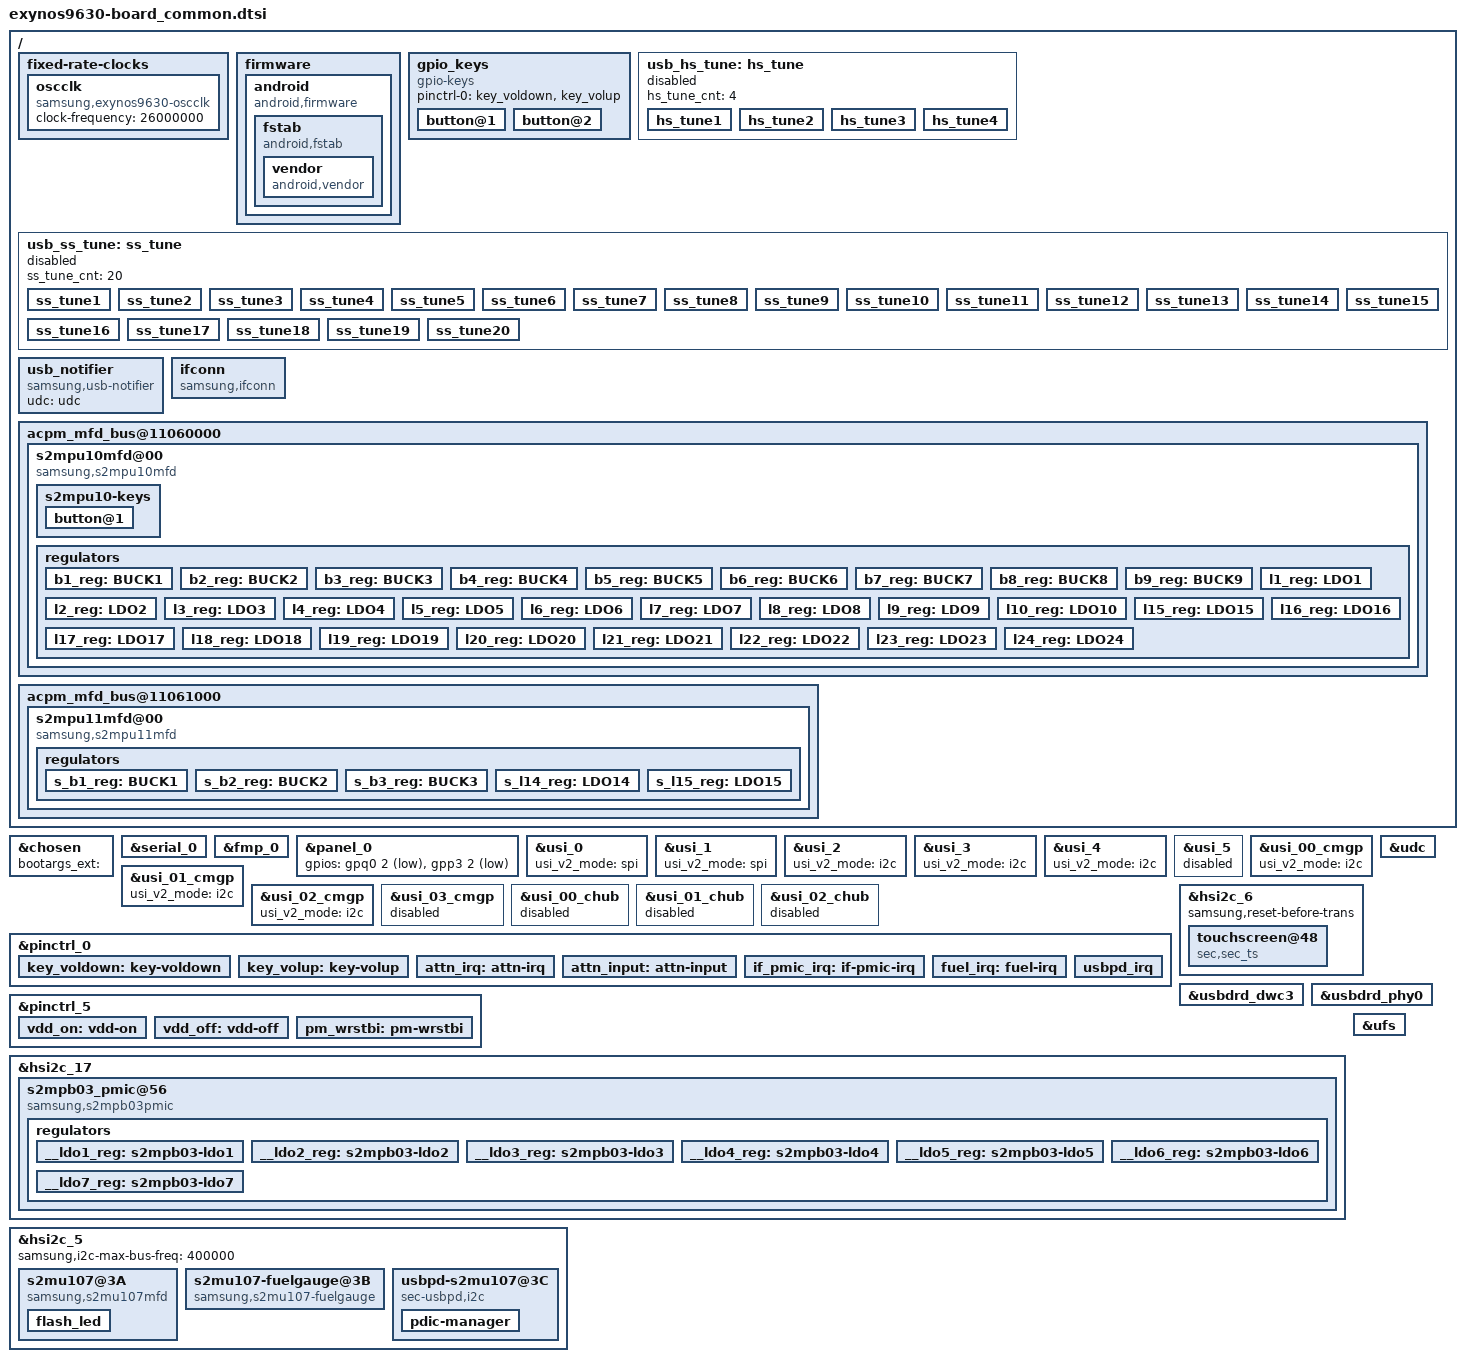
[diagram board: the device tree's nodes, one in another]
/*
 * SAMSUNG EXYNOS9630 board common device tree source
 *
 * Copyright (c) 2019 Samsung Electronics Co., Ltd.
 *		http://www.samsung.com
 *
 * This program is free software; you can redistribute it and/or modify
 * it under the terms of the GNU General Public License version 2 as
 * published by the Free Software Foundation.
 */

#include <dt-bindings/interrupt-controller/exynos9630.h>

/ {
	fragment@common {
		target-path = "/";
		__overlay__ {
			#address-cells = <2>;
			#size-cells = <1>;

			fixed-rate-clocks {
				oscclk {
					compatible = "samsung,exynos9630-oscclk";
					clock-frequency = <26000000>;
				};
			};

			firmware {
				android {
					compatible = "android,firmware";
/*
					vbmeta {
						compatible = "android,vbmeta";
						parts = "vbmeta,boot,system,vendor,dtbo";
					};
*/
					fstab {
						compatible = "android,fstab";
						vendor {
							compatible = "android,vendor";
							dev = "/dev/block/platform/13600000.ufs/by-name/vendor";
							type = "ext4";
							mnt_flags = "ro";
							fsmgr_flags = "wait";
/*
							fsmgr_flags = "wait,avb";
*/
						};
					};
				};
			};

			gpio_keys {
				status = "okay";
				compatible = "gpio-keys";
				pinctrl-names = "default";
				pinctrl-0 = <&key_voldown &key_volup>;

				button@1 {
					label = "gpio-keys: KEY_VOLUMEDOWN";
					linux,code = <114>;
					gpios = <&gpa0 7 0xf>;
				};
				button@2 {
					label = "gpio-keys: KEY_VOLUMEUP";
					linux,code = <115>;
					gpios = <&gpa1 0 0xf>;
				};
			};
			usb_hs_tune:hs_tune {
				status = "disabled";
				hs_tune_cnt = <4>;
				/* value = <device host> */
				hs_tune1 {
					tune_name = "tx_pre_emp";
					tune_value = <0x3 0x3>;
				};

				hs_tune2 {
					tune_name = "tx_vref";
					tune_value = <0xc 0xc>;
				};

				hs_tune3 {
					tune_name = "rx_sqrx";
					tune_value = <0x5 0x5>;
				};

				hs_tune4 {
					tune_name = "utmi_clk";
					tune_value = <0x1 0x1>;
				};
			};

			usb_ss_tune:ss_tune {
				status = "disabled";
				ss_tune_cnt = <20>;
				/* value = <device host> */
				ss_tune1 {
					tune_name = "ssrx_sqhs_th";
					tune_value = <0x4 0x4>;
				};

				ss_tune2 {
					tune_name = "ssrx_lfps_th";
					tune_value = <0x2 0x2>;
				};

				ss_tune3 {
					tune_name = "ssrx_mf_eq_en";
					tune_value = <0x1 0x1>;
				};

				ss_tune4 {
					tune_name = "ssrx_mf_eq_ctrl_ss";
					tune_value = <0x6 0x6>;
				};

				ss_tune5 {
					tune_name = "ssrx_hf_eq_ctrl_ss";
					tune_value = <0xe 0xe>;
				};

				ss_tune6 {
					tune_name = "ssrx_mf_eq_ctrl_ssp";
					tune_value = <0x6 0x6>;
				};

				ss_tune7 {
					tune_name = "ssrx_hf_eq_ctrl_ssp";
					tune_value = <0xe 0xe>;
				};

				ss_tune8 {
					tune_name = "ssrx_dfe1_tap_ctrl";
					tune_value = <0x2 0x2>;
				};

				ss_tune9 {
					tune_name = "ssrx_dfe2_tap_ctrl";
					tune_value = <0x0 0x0>;
				};

				ss_tune10 {
					tune_name = "ssrx_dfe3_tap_ctrl";
					tune_value = <0x0 0x0>;
				};

				ss_tune11 {
					tune_name = "ssrx_dfe4_tap_ctrl";
					tune_value = <0x0 0x0>;
				};

				ss_tune12 {
					tune_name = "ssrx_dfe5_tap_ctrl";
					tune_value = <0x0 0x0>;
				};

				ss_tune13 {
					tune_name = "ssrx_term_cal";
					tune_value = <0xb 0xb>;
				};

				ss_tune14 {
					tune_name = "sstx_amp";
					tune_value = <0xb 0xb>;
				};

				ss_tune15 {
					tune_name = "sstx_deemp";
					tune_value = <0x5 0x5>;
				};

				ss_tune16 {
					tune_name = "sstx_pre_shoot";
					tune_value = <0x3 0x3>;
				};

				ss_tune17 {
					tune_name = "sstx_idrv_up";
					tune_value = <0x7 0x7>;
				};

				ss_tune18 {
					tune_name = "sstx_idrv_dn";
					tune_value = <0x0 0x0>;
				};

				ss_tune19 {
					tune_name = "sstx_up_term";
					tune_value = <0x3 0x3>;
				};

				ss_tune20 {
					tune_name = "sstx_dn_term";
					tune_value = <0x3 0x3>;
				};
			};

			usb_notifier {
				compatible = "samsung,usb-notifier";
				udc = <&udc>;
			};

			ifconn {
				status = "okay";
				compatible = "samsung,ifconn";
				ifconn,usbpd = "s2mu107";
				ifconn,muic = "s2mu107-muic";
			};

			acpm_mfd_bus@11060000 {
				status = "okay";
				#address-cells = <1>;
				#size-cells = <0>;
				s2mpu10mfd@00 {
					compatible = "samsung,s2mpu10mfd";
					acpm-ipc-channel = <2>;
					i2c-speedy-address;
					s2mpu10,wakeup = "enabled";
					reg = <0x00>;
					interrupts = <GIC_SPI INTREQ_COMB_NONSECURE_SYSREG_VGPIO2AP IRQ_TYPE_LEVEL_HIGH>;
					pinctrl-names = "default";
					pinctrl-0 = <&pm_wrstbi &smpl_warn>;
					gpios = <&gpg0 0 0>;
					/* RTC: wtsr/smpl */
					wtsr_en = "enabled"; /* enable */
					smpl_en = "enabled"; /* enable */
					wtsr_timer_val = <3>;	/* 1000ms */
					smpl_timer_val = <4>;	/* 500ms */
					check_jigon = <0>; /* do not check jigon */
					/* RTC: If it's first boot, reset rtc to 1/1/2019 12:00:00(Tue) */
					init_time,sec = <0>;
					init_time,min = <0>;
					init_time,hour = <12>;
					init_time,mday = <1>;
					init_time,mon = <0>;
					init_time,year = <119>;
					init_time,wday = <2>;
					/* SMPL_WARN */
					smpl_warn_en = <1>; /* 1 : enable , 0 : disable */
					/* range of SMPL_WARN_LEVEL */
					/* 0x00 : 2.1V, 0x20 : 2.3V, 0x40 : 2.5V, 0x60 : 2.7V 0x80 : 2.9V */
					/* 0xA0 : 3.1V, 0xC0 : 3.3V */
					smpl_warn_vth = <0x80>;
					/* SMPL_WARN_HYS[4:3] 00(Reserved), 01(200mV), 10(300mV), 11(Reserved) */
					smpl_warn_hys = <0x00>;
					/* OCP_WARN */
					ocp_warn_b2_en = <1>; /* 1 : enable, 0 : disable */
					ocp_warn_b2_cnt = <0>; /* ocp warn reset timing control, 0 : 2 clock, 1 : 32 clock */
					ocp_warn_b2_dvs_mask = <0>; /* ocp warn mask when dvs, 0 : not masked, 1 : masked  */
					ocp_warn_b3_en = <1>; /* 1 : enable, 0 : disable */
					ocp_warn_b3_cnt = <0>; /* ocp warn reset timing control, 0 : 2 clock, 1 : 32 clock */
					ocp_warn_b3_dvs_mask = <0>; /* ocp warn mask when dvs, 0 : not masked, 1 : masked  */

					s2mpu10-keys {
						button@1 {
							label = "pmic-keys: KEY_POWER";
							linux,code = <116>;
							wakeup = <1>;
						};
					};

					regulators {
						b1_reg: BUCK1 {
							regulator-name = "vdd_mif";
							regulator-min-microvolt = <450000>;
							regulator-max-microvolt = <1300000>;
							regulator-always-on;
							regulator-ramp-delay = <12000>;
							regulator-initial-mode = <3>;
						};

						b2_reg: BUCK2 {
							regulator-name = "vdd_cpucl1";
							regulator-min-microvolt = <450000>;
							regulator-max-microvolt = <1300000>;
							regulator-always-on;
							regulator-ramp-delay = <12000>;
							regulator-initial-mode = <3>;
						};

						b3_reg: BUCK3 {
							regulator-name = "vdd_cpucl0";
							regulator-min-microvolt = <450000>;
							regulator-max-microvolt = <1300000>;
							regulator-always-on;
							regulator-ramp-delay = <12000>;
							regulator-initial-mode = <3>;
						};

						b4_reg: BUCK4 {
							regulator-name = "vdd_int";
							regulator-min-microvolt = <450000>;
							regulator-max-microvolt = <1300000>;
							regulator-always-on;
							regulator-ramp-delay = <12000>;
							regulator-initial-mode = <3>;
						};

						b5_reg: BUCK5 {
							regulator-name = "vdd_npu";
							regulator-min-microvolt = <450000>;
							regulator-max-microvolt = <1300000>;
							regulator-always-on;
							regulator-ramp-delay = <12000>;
							regulator-initial-mode = <3>;
						};

						b6_reg: BUCK6 {
							regulator-name = "vdd2_mem";
							regulator-min-microvolt = <900000>;
							regulator-max-microvolt = <1500000>;
							regulator-always-on;
							regulator-ramp-delay = <12000>;
							regulator-initial-mode = <3>;
						};

						b7_reg: BUCK7 {
							regulator-name = "vdd_lldo1";
							regulator-min-microvolt = <900000>;
							regulator-max-microvolt = <1500000>;
							regulator-always-on;
							regulator-ramp-delay = <12000>;
							regulator-initial-mode = <3>;
						};

						b8_reg: BUCK8 {
							regulator-name = "vdd_lldo2";
							regulator-min-microvolt = <900000>;
							regulator-max-microvolt = <1500000>;
							regulator-always-on;
							regulator-ramp-delay = <12000>;
							regulator-initial-mode = <3>;
						};

						b9_reg: BUCK9 {
							regulator-name = "vdd_mldo";
							regulator-min-microvolt = <1750000>;
							regulator-max-microvolt = <2150000>;
							regulator-always-on;
							regulator-ramp-delay = <12000>;
							regulator-initial-mode = <3>;
						};

						l1_reg: LDO1 {
							regulator-name = "vdd_ldo1";
							regulator-min-microvolt = <700000>;
							regulator-max-microvolt = <1300000>;
							regulator-always-on;
							regulator-ramp-delay = <12000>;
							regulator-initial-mode = <3>;
						};

						l2_reg: LDO2 {
							regulator-name = "vdd_ldo2";
							regulator-min-microvolt = <1600000>;
							regulator-max-microvolt = <1950000>;
							regulator-always-on;
							regulator-ramp-delay = <12000>;
							regulator-initial-mode = <3>;
						};

						l3_reg: LDO3 {
							regulator-name = "vdd_ldo3";
							regulator-min-microvolt = <500000>;
							regulator-max-microvolt = <1187500>;
							regulator-always-on;
							regulator-ramp-delay = <12000>;
							regulator-initial-mode = <3>;
						};

						l4_reg: LDO4 {
							regulator-name = "vdd_ldo4";
							regulator-min-microvolt = <700000>;
							regulator-max-microvolt = <1300000>;
							regulator-always-on;
							regulator-ramp-delay = <12000>;
							regulator-initial-mode = <3>;
						};

						l5_reg: LDO5 {
							regulator-name = "vdd_ldo5";
							regulator-min-microvolt = <700000>;
							regulator-max-microvolt = <1300000>;
							regulator-always-on;
							regulator-ramp-delay = <12000>;
							regulator-initial-mode = <3>;
						};

						l6_reg: LDO6 {
							regulator-name = "vdd_ldo6";
							regulator-min-microvolt = <1600000>;
							regulator-max-microvolt = <1950000>;
							regulator-always-on;
							regulator-ramp-delay = <12000>;
							regulator-initial-mode = <3>;
						};

						l7_reg: LDO7 {
							regulator-name = "vdd_ldo7";
							regulator-min-microvolt = <1800000>;
							regulator-max-microvolt = <3375000>;
							regulator-always-on;
							regulator-ramp-delay = <12000>;
							regulator-initial-mode = <3>;
						};

						l8_reg: LDO8 {
							regulator-name = "vdd_ldo8";
							regulator-min-microvolt = <700000>;
							regulator-max-microvolt = <1300000>;
							regulator-always-on;
							regulator-ramp-delay = <12000>;
							regulator-initial-mode = <3>;
						};

						l9_reg: LDO9 {
							regulator-name = "vdd_ldo9";
							regulator-min-microvolt = <1600000>;
							regulator-max-microvolt = <1950000>;
							regulator-always-on;
							regulator-ramp-delay = <12000>;
							regulator-initial-mode = <3>;
						};

						l10_reg: LDO10 {
							regulator-name = "vdd_ldo10";
							regulator-min-microvolt = <1800000>;
							regulator-max-microvolt = <3375000>;
							regulator-always-on;
							regulator-ramp-delay = <12000>;
							regulator-initial-mode = <3>;
						};
/*
						l11_reg: LDO11 {
							regulator-name = "vdd_ldo11";
							regulator-min-microvolt = <450000>;
							regulator-max-microvolt = <1300000>;
							regulator-always-on;
							regulator-ramp-delay = <12000>;
							regulator-initial-mode = <3>;
						};

						l12_reg: LDO12 {
							regulator-name = "vdd_ldo12";
							regulator-min-microvolt = <700000>;
							regulator-max-microvolt = <1300000>;
							regulator-always-on;
							regulator-ramp-delay = <12000>;
							regulator-initial-mode = <3>;
						};

						l13_reg: LDO13 {
							regulator-name = "vdd_ldo13";
							regulator-min-microvolt = <700000>;
							regulator-max-microvolt = <1300000>;
							regulator-always-on;
							regulator-ramp-delay = <12000>;
							regulator-initial-mode = <3>;
						};

						l14_reg: LDO14 {
							regulator-name = "vdd_ldo14";
							regulator-min-microvolt = <1600000>;
							regulator-max-microvolt = <1950000>;
							regulator-always-on;
							regulator-ramp-delay = <12000>;
							regulator-initial-mode = <3>;
						};
*/
						l15_reg: LDO15 {
							regulator-name = "vdd_ldo15";
							regulator-min-microvolt = <1800000>;
							regulator-max-microvolt = <3375000>;
							regulator-always-on;
							regulator-ramp-delay = <12000>;
							regulator-initial-mode = <3>;
						};

						l16_reg: LDO16 {
							regulator-name = "vdd_ldo16";
							regulator-min-microvolt = <1800000>;
							regulator-max-microvolt = <3375000>;
							regulator-always-on;
							regulator-ramp-delay = <12000>;
							regulator-initial-mode = <3>;
						};

						l17_reg: LDO17 {
							regulator-name = "vdd_ldo17";
							regulator-min-microvolt = <1600000>;
							regulator-max-microvolt = <1950000>;
							regulator-ramp-delay = <12000>;
							regulator-initial-mode = <3>;
						};

						l18_reg: LDO18 {
							regulator-name = "vdd_ldo18";
							regulator-min-microvolt = <1800000>;
							regulator-max-microvolt = <3375000>;
							regulator-ramp-delay = <12000>;
							regulator-initial-mode = <3>;
						};

						l19_reg: LDO19 {
							regulator-name = "vdd_ldo19";
							regulator-min-microvolt = <1800000>;
							regulator-max-microvolt = <3375000>;
							regulator-always-on;
							regulator-ramp-delay = <12000>;
							regulator-initial-mode = <3>;
						};

						l20_reg: LDO20 {
							regulator-name = "vdd_ldo20";
							regulator-min-microvolt = <1600000>;
							regulator-max-microvolt = <1950000>;
							regulator-always-on;
							regulator-ramp-delay = <12000>;
							regulator-initial-mode = <3>;
						};

						l21_reg: LDO21 {
							regulator-name = "vdd_ldo21";
							regulator-min-microvolt = <1800000>;
							regulator-max-microvolt = <3375000>;
							regulator-always-on;
							regulator-ramp-delay = <12000>;
							regulator-initial-mode = <3>;
						};

						l22_reg: LDO22 {
							regulator-name = "vdd_ldo22";
							regulator-min-microvolt = <1600000>;
							regulator-max-microvolt = <1950000>;
							regulator-always-on;
							regulator-ramp-delay = <12000>;
							regulator-initial-mode = <3>;
						};

						l23_reg: LDO23 {
							regulator-name = "vdd_ldo23";
							regulator-min-microvolt = <1800000>;
							regulator-max-microvolt = <3375000>;
							regulator-always-on;
							regulator-ramp-delay = <12000>;
							regulator-initial-mode = <3>;
						};

						l24_reg: LDO24 {
							regulator-name = "vdd_ldo24";
							regulator-min-microvolt = <1800000>;
							regulator-max-microvolt = <3375000>;
							regulator-always-on;
							regulator-ramp-delay = <12000>;
							regulator-initial-mode = <3>;
						};
					}; /* end of regulators */
				}; /* end of s2mpu10mfd@00 */
			}; /* end of acpm_mfd_bus@11a10000 */

			acpm_mfd_bus@11061000 {
				status = "okay";
				#address-cells = <1>;
				#size-cells = <0>;
				s2mpu11mfd@00 { /* TODO: node check */
					compatible = "samsung,s2mpu11mfd";
					acpm-ipc-channel = <2>;
					i2c-speedy-address;
					s2mpu11,wakeup = "enabled";
					reg = <0x00>; /* TODO: Check */
					wtsr_en = <1>; /* 0 : disable, 1: enable */
					/* OCP_WARN */
					ocp_warn_b2_en = <1>; /* 1 : enable, 0 : disable */
					ocp_warn_b2_cnt = <0>; /* ocp warn reset timing control, 0 : 2 clock, 1 : 32 clock */
					ocp_warn_b2_dvs_mask = <0>; /* ocp warn mask when dvs, 0 : not masked, 1 : masked  */

					regulators {
						s_b1_reg: BUCK1 {
							regulator-name = "vdd_cam";
							regulator-min-microvolt = <500000>;
							regulator-max-microvolt = <1200000>;
							regulator-always-on;
							regulator-ramp-delay = <6000>;
							regulator-initial-mode = <3>;
						};

						s_b2_reg: BUCK2 {
							regulator-name = "vdd_g3d";
							regulator-min-microvolt = <500000>;
							regulator-max-microvolt = <1200000>;
							regulator-always-on;
							regulator-ramp-delay = <6000>;
							regulator-initial-mode = <3>;
						};

						s_b3_reg: BUCK3 {
							regulator-name = "vdd_ppc_m";
							regulator-min-microvolt = <500000>;
							regulator-max-microvolt = <1200000>;
							regulator-always-on;
							regulator-ramp-delay = <6000>;
							regulator-initial-mode = <3>;
						};
/*
						s_b4_reg: BUCK4{
							regulator-name = "vdd_cpg_wb";
							regulator-min-microvolt = <500000>;
							regulator-max-microvolt = <1200000>;
							regulator-always-on;
							regulator-ramp-delay = <6000>;
							regulator-initial-mode = <2>;
						};

						s_b5_reg: BUCK5 {
							regulator-name = "vdd_cp_cpu";
							regulator-min-microvolt = <500000>;
							regulator-max-microvolt = <1200000>;
							regulator-always-on;
							regulator-ramp-delay = <6000>;
							regulator-initial-mode = <3>;
						};

						s_l1_reg: LDO1 {
							regulator-name = "vdd_ldo1";
							regulator-min-microvolt = <700000>;
							regulator-max-microvolt = <1300000>;
							regulator-ramp-delay = <12000>;
							regulator-initial-mode = <3>;
						};

						s_l2_reg: LDO2 {
							regulator-name = "vdd_ldo2";
							regulator-min-microvolt = <700000>;
							regulator-max-microvolt = <1300000>;
							regulator-ramp-delay = <12000>;
							regulator-initial-mode = <3>;
						};

						s_l3_reg: LDO3 {
							regulator-name = "vdd_ldo3";
							regulator-min-microvolt = <1600000>;
							regulator-max-microvolt = <1950000>;
							regulator-ramp-delay = <12000>;
							regulator-initial-mode = <3>;
						};

						s_l4_reg: LDO4 {
							regulator-name = "vdd_ldo4";
							regulator-min-microvolt = <1600000>;
							regulator-max-microvolt = <1950000>;
							regulator-ramp-delay = <12000>;
							regulator-initial-mode = <3>;
						};

						s_l5_reg: LDO5 {
							regulator-name = "vdd_ldo5";
							regulator-min-microvolt = <1800000>;
							regulator-max-microvolt = <3375000>;
							regulator-ramp-delay = <12000>;
							regulator-initial-mode = <3>;
						};

						s_l6_reg: LDO6 {
							regulator-name = "vdd_ldo6";
							regulator-min-microvolt = <700000>;
							regulator-max-microvolt = <1300000>;
							regulator-ramp-delay = <12000>;
							regulator-initial-mode = <2>;
						};

						s_l7_reg: LDO7 {
							regulator-name = "vdd_ldo7";
							regulator-min-microvolt = <1800000>;
							regulator-max-microvolt = <1950000>;
							regulator-ramp-delay = <12000>;
							regulator-initial-mode = <2>;
						};

						s_l8_reg: LDO8 {
							regulator-name = "vdd_ldo8";
							regulator-min-microvolt = <700000>;
							regulator-max-microvolt = <1300000>;
							regulator-ramp-delay = <12000>;
							regulator-initial-mode = <2>;
						};

						s_l9_reg: LDO9 {
							regulator-name = "vdd_ldo9";
							regulator-min-microvolt = <700000>;
							regulator-max-microvolt = <1300000>;
							regulator-ramp-delay = <12000>;
							regulator-initial-mode = <2>;
						};

						s_l10_reg: LDO10 {
							regulator-name = "vdd_ldo10";
							regulator-min-microvolt = <1600000>;
							regulator-max-microvolt = <1950000>;
							regulator-ramp-delay = <12000>;
							regulator-initial-mode = <2>;
						};

						s_l11_reg: LDO11 {
							regulator-name = "vdd_ldo11";
							regulator-min-microvolt = <1600000>;
							regulator-max-microvolt = <1950000>;
							regulator-ramp-delay = <12000>;
							regulator-initial-mode = <2>;
						};

						s_l12_reg: LDO12 {
							regulator-name = "vdd_ldo12";
							regulator-min-microvolt = <1800000>;
							regulator-max-microvolt = <3375000>;
							regulator-ramp-delay = <12000>;
							regulator-initial-mode = <1>;
						};

						s_l13_reg: LDO13 {
							regulator-name = "vdd_ldo13";
							regulator-min-microvolt = <1800000>;
							regulator-max-microvolt = <3375000>;
							regulator-ramp-delay = <12000>;
							regulator-initial-mode = <1>;
						};
*/
						s_l14_reg: LDO14 {
							regulator-name = "vdd_aldo1";
							regulator-min-microvolt = <1600000>;
							regulator-max-microvolt = <1950000>;
							regulator-always-on;
							regulator-ramp-delay = <12000>;
							regulator-initial-mode = <3>;
						};

						s_l15_reg: LDO15 {
							regulator-name = "vdd_aldo2";
							regulator-min-microvolt = <700000>;
							regulator-max-microvolt = <1300000>;
							regulator-always-on;
							regulator-ramp-delay = <12000>;
							regulator-initial-mode = <3>;
						};
					}; /* end of regulators */
				}; /* end of s2mpu11mfd@00 */
			}; /* end of acpm_mfd_bus@11061000 */
		}; /* end of __overlay__ */
	}; /* end of fragment */
}; /* end of root */

&chosen {
	bootargs_ext = "";
};

&serial_0 {
	status = "okay";
};

&fmp_0 {
	exynos,block-type = "sda";
	exynos,fips-block_offset = <5>;
};

&panel_0 {
	/* reset, power */
	gpios = <&gpq0 2 0x1>, <&gpp3 2 0x1>;
};

/* USI_00 */
&usi_0 {
	usi_v2_mode = "spi";
	status = "okay";
};

/* USI_01 */
&usi_1 {
	usi_v2_mode = "spi";
	status = "okay";
};

/* USI_02 */
&usi_2 {
	usi_v2_mode = "i2c";
	status = "okay";
};

/* USI_03 */
&usi_3 {
	usi_v2_mode = "i2c";
	status = "okay";
};

/* USI_04 */
&usi_4 {
	usi_v2_mode = "i2c";
	status = "okay";
};

/* USI_05 */
&usi_5 {
	/*	usi_v2_mode = "i2c" or "spi" or "uart"	*/
	status = "disabled";
};

/* USI_00_CMGP */
&usi_00_cmgp {
	usi_v2_mode = "i2c";
	status = "okay";
};

/* USI_01_CMGP */
&usi_01_cmgp {
	usi_v2_mode = "i2c";
	status = "okay";
};

/* USI_02_CMGP */
&usi_02_cmgp {
	usi_v2_mode = "i2c";
	status = "okay";
};

/* USI_03_CMGP */
&usi_03_cmgp {
	/*	usi_v2_mode = "i2c" or "spi" or "uart"	*/
	status = "disabled";
};

/* USI_00_CHUB */
&usi_00_chub {
	/*	usi_v2_mode = "i2c" or "spi" or "uart"	*/
	status = "disabled";
};

/* USI_01_CHUB */
&usi_01_chub {
	/*	usi_v2_mode = "i2c" or "spi" or "uart"	*/
	status = "disabled";
};

/* USI_02_CHUB */
&usi_02_chub {
	/*	usi_v2_mode = "i2c" or "spi" or "uart"	*/
	status = "disabled";
};

&pinctrl_0 {
	key_voldown: key-voldown {
		samsung,pins = "gpa0-7";
		samsung,pin-function = <0xf>;
		samsung,pin-pud = <0>;
		samsung,pin-drv = <0>;
	};

	key_volup: key-volup {
		samsung,pins = "gpa1-0";
		samsung,pin-function = <0xf>;
		samsung,pin-pud = <0>;
		samsung,pin-drv = <0>;
	};

	attn_irq: attn-irq {
		samsung,pins = "gpa0-3";
		samsung,pin-function = <0xf>;
		samsung,pin-pud = <3>;
		samsung,pin-drv = <3>;
	};

	attn_input: attn-input {
		samsung,pins = "gpa0-3";
		samsung,pin-function = <0>;
		samsung,pin-pud = <1>;
	};

	if_pmic_irq: if-pmic-irq {
		samsung,pins = "gpa0-4";
		samsung,pin-function = <0>;
		samsung,pin-pud = <0>;
		samsung,pin-drv = <0>;
	};

	fuel_irq: fuel-irq {
		samsung,pins = "gpa0-6";
		samsung,pin-function = <0>;
		samsung,pin-pud = <2>;
		samsung,pin-drv = <0>;
	};

	usbpd_irq: usbpd_irq {
		samsung,pins = "gpa0-5";
		samsung,pin-function = <0xf>;
		samsung,pin-pud = <3>;
		samsung-pin-drv = <3>;
	};
};

&pinctrl_5 {
	vdd_on: vdd-on {
		samsung,pins = "gpp3-3";
		samsung,pin-function = <1>;
		samsung,pin-val = <1>;
		samsung,pin-pud = <3>;
		samsung,pin-drv = <3>;
	};

	vdd_off: vdd-off {
		samsung,pins = "gpp3-3";
		samsung,pin-functon = <1>;
		samsung,pin-val = <0>;
		samsung,pin-pud = <1>;
		samsung,pin-drv = <3>;
	};

	pm_wrstbi: pm-wrstbi {
		samsung,pins = "gpg2-0";
		samsung,pin-con-pdn = <3>;
	};
};

&hsi2c_6 {
	#address-cells = <1>;
	#size-cells = <0>;
	status = "okay";
	samsung,reset-before-trans;
	touchscreen@48 {
		compatible = "sec,sec_ts";
		reg = <0x48>;
		pinctrl-names = "on_state", "off_state";
		pinctrl-0 = <&attn_irq &vdd_on>;
		pinctrl-1 = <&attn_input &vdd_off>;
		pressure-sensor = "Y";
		sec,irq_gpio = <&gpa0 3 0>;
		sec,irq_type = <8200>;
		sec,max_coords = <4095 4095>;
		sec,mis_cal_check = <1>;
//		sec,regulator_avdd = "";
//		sec,regulator_boot_on;
//		sec,always_lpmode = <1>;
		sec,project_name = "neus";
		sec,firmware_name = "tsp_sec/y761_dream1.fw", "tsp_sec/y761_dream1.fw";
	};
};
&udc {
	status = "okay";
};

&usbdrd_dwc3 {
	dr_mode = "otg";
	maximum-speed = "high-speed";
	snps,quirk-frame-length-adjustment = <0x20>;
	snps,u1u2_exitfail_quirk;
	/* ux_exit_in_px should be defined in MK, LT */
	snps,ux_exit_in_px_quirk;
	/* elastic_buf_mode_quirk should be defined in MK */
	snps,elastic_buf_mode_quirk;
	/* usb3-lpm-capable;
	snps,usb3_lpm_capable;
	adj-sof-accuracy = <1>; */
	/*
	 * dis-u2-freeclk-exists-quirk, dis_u2_susphy_quirk are alternative.
	 * One of them should be selected
	 */
	snps,dis-u2-freeclk-exists-quirk;
	/*snps,dis_u2_susphy_quirk;*/

	usb_audio_offloading = <0>;
//	abox = <&abox>; /* Temporary block */
};

&usbdrd_phy0 {
	status = "okay";
	usb3phy-isolation= <1>;
	pinctrl-names = "default";
//	pinctrl-0 = <&phy_port>;
//	phy,gpio_phy_port = <&gpg0 4 0x0>;
	hs_tune_param = <&usb_hs_tune>;
	ss_tune_param = <&usb_ss_tune>;
};

&hsi2c_17 {
	#address-cells = <1>;
	#size-cells = <0>;
	status = "okay";
	s2mpb03_pmic@56 { /* TODO: check */
		compatible = "samsung,s2mpb03pmic";
		reg = <0x56>;

		s2mpb03,wakeup;

		regulators {
			__ldo1_reg: s2mpb03-ldo1 {
				regulator-name = "VDDD_1.0V_CAM";
				regulator-min-microvolt = <1025000>;
				regulator-max-microvolt = <1025000>;
			};

			__ldo2_reg: s2mpb03-ldo2 {
				regulator-name = "VDDQ_1.1V_CAM";
				regulator-min-microvolt = <1100000>;
				regulator-max-microvolt = <1100000>;
			};

			__ldo3_reg: s2mpb03-ldo3 {
				regulator-name = "VDDIO_1.8V_CAM";
				regulator-min-microvolt = <1800000>;
				regulator-max-microvolt = <1800000>;
			};

			__ldo4_reg: s2mpb03-ldo4 {
				regulator-name = "VDDD_RET_1.0V_CAM";
				regulator-min-microvolt = <700000>;
				regulator-max-microvolt = <1025000>;
			};

			__ldo5_reg: s2mpb03-ldo5 {
				regulator-name = "VDDA_2.4V_CAM";
				regulator-min-microvolt = <2400000>;
				regulator-max-microvolt = <2400000>;
			};

			__ldo6_reg: s2mpb03-ldo6 {
				regulator-name = "VDDA_2.8V_CAM";
				regulator-min-microvolt = <2800000>;
				regulator-max-microvolt = <2800000>;
			};

			__ldo7_reg: s2mpb03-ldo7 {
				regulator-name = "VDD_VM_2.8V_OIS";
				regulator-min-microvolt = <2800000>;
				regulator-max-microvolt = <2800000>;
			};
		};
	};
};

&hsi2c_5 {
	#address-cells = <1>;
	#size-cells = <0>;
	status = "okay";
	samsung,i2c-max-bus-freq = <400000>;
	s2mu107@3A {
		status = "okay";
		compatible = "samsung,s2mu107mfd";
		reg = <0x3A>;
		pinctrl-names = "default";
		pinctrl-0 = <&if_pmic_irq>;
		s2mu107,irq-gpio = <&gpa0 4 1>;
		s2mu107,wakeup;
		flash_led {
			flash-gpio = <&gpp2 2 0>;
			torch-gpio = <&gpp2 3 0>;
			flash_current = <1400>;
			torch_current = <125>;
			status = "okay";
		};
	};

	s2mu107-fuelgauge@3B {
		compatible = "samsung,s2mu107-fuelgauge";
		reg = <0x3B>;
		pinctrl-names = "default";
		pinctrl-0 = <&fuel_irq>;
		fuelgauge,charger_name = "s2mu107-switching-charger";
		fuelgauge,fuel_int = <&gpa0 6 0>;
		fuelgauge,fuel_alert_soc = <1>;
		fuelgauge,fuel_alert_vol = <3300>;
		fuelgauge,low_temp_limit = <100>;
		fuelgauge,low_vbat_threshold = <3400>;
	};

	usbpd-s2mu107@3C {
		compatible = "sec-usbpd,i2c";
		reg = <0x3C>;
		pinctrl-names = "default";
		pinctrl-0 = <&usbpd_irq>;
		usbpd,usbpd_int = <&gpa0 5 0>;

		pdic-manager {
			/* sink */
			pdic,max_power = <5000>;
			pdic_op_power = <2500>;
			pdic_max_voltage = <6000>;
			pdic_max_current = <2000>;
			pdic,min_current = <500>;

			pdic,giveback = <0>;
			pdic,usb_com_capable = <1>;
			pdic,no_usb_suspend = <1>;

			/* source */
			source,max_voltage = <5000>;
			source,min_voltage = <4000>;
			source,max_power = <2500>;

			/* sink cap */
			sink,capable_max_voltage = <5000>;
		};
	};
};

&ufs {
	vcc-supply = <&l18_reg>;
	vccq2-supply = <&l17_reg>;
	vcc-max-microamp = <3375000>;
	vccq2-max-microamp = <2275000>;
};
